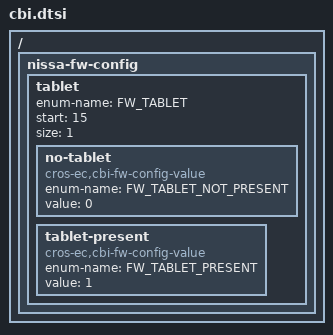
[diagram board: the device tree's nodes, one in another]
/* Copyright 2022 The ChromiumOS Authors
 * Use of this source code is governed by a BSD-style license that can be
 * found in the LICENSE file.
 */

/ {
	/* Pujjogatwin-specific fw_config fields. */
	nissa-fw-config {
		/*
		 * FW_CONFIG field for tablet present or not.
		 */
		tablet {
			enum-name = "FW_TABLET";
			start = <15>;
			size = <1>;

			no-tablet {
				compatible = "cros-ec,cbi-fw-config-value";
				enum-name = "FW_TABLET_NOT_PRESENT";
				value = <0>;
			};
			tablet-present {
				compatible = "cros-ec,cbi-fw-config-value";
				enum-name = "FW_TABLET_PRESENT";
				value = <1>;
			};
		};
	};
};
